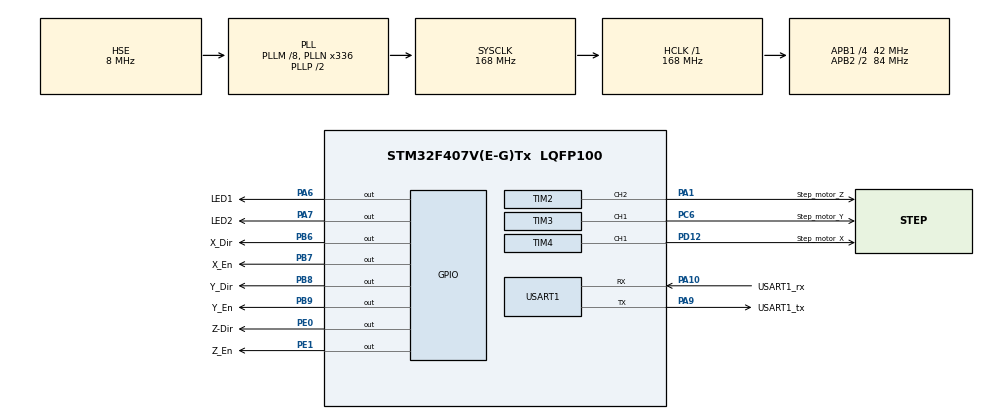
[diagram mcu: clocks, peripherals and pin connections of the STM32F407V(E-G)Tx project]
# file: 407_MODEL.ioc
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Dma.Request0=USART1_RX
Dma.USART1_RX.0.Direction=DMA_PERIPH_TO_MEMORY
Dma.USART1_RX.0.FIFOMode=DMA_FIFOMODE_DISABLE
Dma.USART1_RX.0.Instance=DMA2_Stream2
Dma.USART1_RX.0.MemDataAlignment=DMA_MDATAALIGN_BYTE
Dma.USART1_RX.0.MemInc=DMA_MINC_ENABLE
Dma.USART1_RX.0.Mode=DMA_NORMAL
Dma.USART1_RX.0.PeriphDataAlignment=DMA_PDATAALIGN_BYTE
Dma.USART1_RX.0.PeriphInc=DMA_PINC_DISABLE
Dma.USART1_RX.0.Priority=DMA_PRIORITY_HIGH
Mcu.Family=STM32F4
Mcu.Name=STM32F407V(E-G)Tx
Mcu.Package=LQFP100
NVIC.DMA2_Stream2_IRQn=true\:0\:2\:true\:false\:true\:false
NVIC.PriorityGroup=NVIC_PRIORITYGROUP_2
NVIC.TIM1_TRG_COM_TIM11_IRQn=true\:1\:0\:true\:false\:true\:true
NVIC.TIM1_UP_TIM10_IRQn=true\:1\:0\:true\:false\:true\:true
NVIC.TIM2_IRQn=true\:1\:1\:true\:false\:true\:true
NVIC.TIM3_IRQn=true\:1\:2\:true\:false\:true\:true
NVIC.TIM4_IRQn=true\:1\:3\:true\:false\:true\:true
NVIC.USART1_IRQn=true\:0\:1\:true\:false\:true\:true
PA1.GPIO_Label=Step_motor_Z
PA1.GPIO_Speed=GPIO_SPEED_FREQ_HIGH
PA1.Signal=S_TIM2_CH2
PA10.GPIO_Label=USART1_rx
PA10.Mode=Asynchronous
PA10.Signal=USART1_RX
PA6.GPIO_Label=LED1
PA6.GPIO_Speed=GPIO_SPEED_FREQ_HIGH
PA6.PinState=GPIO_PIN_SET
PA6.Signal=GPIO_Output
PA7.GPIO_Label=LED2
PA7.GPIO_Speed=GPIO_SPEED_FREQ_HIGH
PA7.PinState=GPIO_PIN_SET
PA7.Signal=GPIO_Output
PA9.GPIO_Label=USART1_tx
PA9.Mode=Asynchronous
PA9.Signal=USART1_TX
PB6.GPIO_Label=X_Dir
PB6.GPIO_Speed=GPIO_SPEED_FREQ_HIGH
PB6.PinState=GPIO_PIN_SET
PB6.Signal=GPIO_Output
PB7.GPIO_Label=X_En
PB7.GPIO_Speed=GPIO_SPEED_FREQ_HIGH
PB7.PinState=GPIO_PIN_SET
PB7.Signal=GPIO_Output
PB8.GPIO_Label=Y_Dir
PB8.GPIO_Speed=GPIO_SPEED_FREQ_HIGH
PB8.PinState=GPIO_PIN_SET
PB8.Signal=GPIO_Output
PB9.GPIO_Label=Y_En
PB9.GPIO_Speed=GPIO_SPEED_FREQ_MEDIUM
PB9.PinState=GPIO_PIN_SET
PB9.Signal=GPIO_Output
PC6.GPIO_Label=Step_motor_Y
PC6.GPIO_Speed=GPIO_SPEED_FREQ_HIGH
PC6.Signal=S_TIM3_CH1
PD12.GPIO_Label=Step_motor_X
PD12.GPIO_Speed=GPIO_SPEED_FREQ_HIGH
PD12.Signal=S_TIM4_CH1
PE0.GPIO_Label=Z-Dir
PE0.GPIO_Speed=GPIO_SPEED_FREQ_HIGH
PE0.Signal=GPIO_Output
PE1.GPIO_Label=Z_En
PE1.GPIO_Speed=GPIO_SPEED_FREQ_HIGH
PE1.PinState=GPIO_PIN_SET
PE1.Signal=GPIO_Output
PH0-OSC_IN.Mode=HSE-External-Oscillator
PH0-OSC_IN.Signal=RCC_OSC_IN
PH1-OSC_OUT.Mode=HSE-External-Oscillator
PH1-OSC_OUT.Signal=RCC_OSC_OUT
ProjectManager.HeapSize=0x200
ProjectManager.StackSize=0x400
ProjectManager.TargetToolchain=MDK-ARM V5
RCC.48MHZClocksFreq_Value=84000000
RCC.AHBFreq_Value=168000000
RCC.APB1CLKDivider=RCC_HCLK_DIV4
RCC.APB1Freq_Value=42000000
RCC.APB1TimFreq_Value=84000000
RCC.APB2CLKDivider=RCC_HCLK_DIV2
RCC.APB2Freq_Value=84000000
RCC.APB2TimFreq_Value=168000000
RCC.CortexFreq_Value=168000000
RCC.HCLKFreq_Value=168000000
RCC.HSE_VALUE=8000000
RCC.HSI_VALUE=16000000
RCC.LSE_VALUE=32768
RCC.PLLM=8
RCC.PLLN=336
RCC.PLLSourceVirtual=RCC_PLLSOURCE_HSE
RCC.SYSCLKFreq_VALUE=168000000
RCC.SYSCLKSource=RCC_SYSCLKSOURCE_PLLCLK
RCC.VCOOutputFreq_Value=336000000
SH.S_TIM2_CH2.0=TIM2_CH2,PWM Generation2 CH2
SH.S_TIM3_CH1.0=TIM3_CH1,PWM Generation1 CH1
SH.S_TIM4_CH1.0=TIM4_CH1,Output Compare1 CH1
TIM1.Period=1000
TIM1.Prescaler=83
TIM1.RepetitionCounter=2
TIM2.Channel-PWM\ Generation2\ CH2=TIM_CHANNEL_2
TIM2.Period=5000
TIM2.Prescaler=83
TIM2.Pulse-PWM\ Generation2\ CH2=2500
TIM3.Channel-PWM\ Generation1\ CH1=TIM_CHANNEL_1
TIM3.Period=5000
TIM3.Prescaler=83
TIM3.Pulse-PWM\ Generation1\ CH1=2500
TIM4.Channel-Output\ Compare1\ CH1=TIM_CHANNEL_1
TIM4.Period=5000
TIM4.Prescaler=83
TIM4.Pulse-Output\ Compare1\ CH1=2500
USART1.VirtualMode=VM_ASYNC
VP_TIM1_VS_ClockSourceINT.Mode=Internal
VP_TIM2_VS_ClockSourceINT.Mode=Internal
VP_TIM3_VS_ClockSourceINT.Mode=Internal
VP_TIM4_VS_ClockSourceINT.Mode=Internal
board=407_MODEL

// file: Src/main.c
/**
  ******************************************************************************
  * @file           : main.c
  * @brief          : Main program body
  ******************************************************************************
  ** This notice applies to any and all portions of this file
  * that are not between comment pairs USER CODE BEGIN and
  * USER CODE END. Other portions of this file, whether
  * inserted by the user or by software development tools
  * are owned by their respective copyright owners.
  *
  * COPYRIGHT(c) 2018 STMicroelectronics
  *
  * Redistribution and use in source and binary forms, with or without modification,
  * are permitted provided that the following conditions are met:
  *   1. Redistributions of source code must retain the above copyright notice,
  *      this list of conditions and the following disclaimer.
  *   2. Redistributions in binary form must reproduce the above copyright notice,
  *      this list of conditions and the following disclaimer in the documentation
  *      and/or other materials provided with the distribution.
  *   3. Neither the name of STMicroelectronics nor the names of its contributors
  *      may be used to endorse or promote products derived from this software
  *      without specific prior written permission.
  *
  * THIS SOFTWARE IS PROVIDED BY THE COPYRIGHT HOLDERS AND CONTRIBUTORS "AS IS"
  * AND ANY EXPRESS OR IMPLIED WARRANTIES, INCLUDING, BUT NOT LIMITED TO, THE
  * IMPLIED WARRANTIES OF MERCHANTABILITY AND FITNESS FOR A PARTICULAR PURPOSE ARE
  * DISCLAIMED. IN NO EVENT SHALL THE COPYRIGHT HOLDER OR CONTRIBUTORS BE LIABLE
  * FOR ANY DIRECT, INDIRECT, INCIDENTAL, SPECIAL, EXEMPLARY, OR CONSEQUENTIAL
  * DAMAGES (INCLUDING, BUT NOT LIMITED TO, PROCUREMENT OF SUBSTITUTE GOODS OR
  * SERVICES; LOSS OF USE, DATA, OR PROFITS; OR BUSINESS INTERRUPTION) HOWEVER
  * CAUSED AND ON ANY THEORY OF LIABILITY, WHETHER IN CONTRACT, STRICT LIABILITY,
  * OR TORT (INCLUDING NEGLIGENCE OR OTHERWISE) ARISING IN ANY WAY OUT OF THE USE
  * OF THIS SOFTWARE, EVEN IF ADVISED OF THE POSSIBILITY OF SUCH DAMAGE.
  *
  ******************************************************************************
  */
#include "main.h"
#include "stm32f4xx_hal.h"

TIM_HandleTypeDef htim1;
TIM_HandleTypeDef htim2;
TIM_HandleTypeDef htim3;
TIM_HandleTypeDef htim4;

UART_HandleTypeDef huart1;
DMA_HandleTypeDef hdma_usart1_rx;

/* USER CODE BEGIN PV */
/* Private variables ---------------------------------------------------------*/

/* USER CODE END PV */

void SystemClock_Config(void);
static void MX_GPIO_Init(void);
static void MX_DMA_Init(void);
static void MX_TIM1_Init(void);
static void MX_TIM2_Init(void);
static void MX_TIM3_Init(void);
static void MX_TIM4_Init(void);
static void MX_USART1_UART_Init(void);

void HAL_TIM_MspPostInit(TIM_HandleTypeDef *htim);

/* USER CODE BEGIN PFP */
/* Private function prototypes -----------------------------------------------*/

/* USER CODE END PFP */

int main(void)
{

  /* MCU Configuration----------------------------------------------------------*/

  /* Reset of all peripherals, Initializes the Flash interface and the Systick. */
  HAL_Init();

  /* Configure the system clock */
  SystemClock_Config();

  /* Initialize all configured peripherals */
  MX_GPIO_Init();
  MX_DMA_Init();
  MX_TIM1_Init();
  MX_TIM2_Init();
  MX_TIM3_Init();
  MX_TIM4_Init();
  MX_USART1_UART_Init();
  /* USER CODE BEGIN 2 */
  HAL_TIM_PWM_Start(&htim2, TIM_CHANNEL_2);
  /* USER CODE END 2 */

  /* Infinite loop */
  /* USER CODE BEGIN WHILE */
  while (1)
  {
		HAL_GPIO_WritePin(GPIOA, LED1_Pin|LED2_Pin, GPIO_PIN_RESET);
		HAL_Delay(1000);
		HAL_GPIO_WritePin(GPIOA, LED1_Pin|LED2_Pin, GPIO_PIN_SET);
		HAL_Delay(1000);
  /* USER CODE END WHILE */

  }

}

void SystemClock_Config(void)
{

  RCC_OscInitTypeDef RCC_OscInitStruct;
  RCC_ClkInitTypeDef RCC_ClkInitStruct;

    /**Configure the main internal regulator output voltage
    */
  __HAL_RCC_PWR_CLK_ENABLE();

  __HAL_PWR_VOLTAGESCALING_CONFIG(PWR_REGULATOR_VOLTAGE_SCALE1);

    /**Initializes the CPU, AHB and APB busses clocks
    */
  RCC_OscInitStruct.OscillatorType = RCC_OSCILLATORTYPE_HSE;
  RCC_OscInitStruct.HSEState = RCC_HSE_ON;
  RCC_OscInitStruct.PLL.PLLState = RCC_PLL_ON;
  RCC_OscInitStruct.PLL.PLLSource = RCC_PLLSOURCE_HSE;
  RCC_OscInitStruct.PLL.PLLM = 8;
  RCC_OscInitStruct.PLL.PLLN = 336;
  RCC_OscInitStruct.PLL.PLLP = RCC_PLLP_DIV2;
  RCC_OscInitStruct.PLL.PLLQ = 4;
  if (HAL_RCC_OscConfig(&RCC_OscInitStruct) != HAL_OK)
  {
    _Error_Handler(__FILE__, __LINE__);
  }

    /**Initializes the CPU, AHB and APB busses clocks
    */
  RCC_ClkInitStruct.ClockType = RCC_CLOCKTYPE_HCLK|RCC_CLOCKTYPE_SYSCLK
                              |RCC_CLOCKTYPE_PCLK1|RCC_CLOCKTYPE_PCLK2;
  RCC_ClkInitStruct.SYSCLKSource = RCC_SYSCLKSOURCE_PLLCLK;
  RCC_ClkInitStruct.AHBCLKDivider = RCC_SYSCLK_DIV1;
  RCC_ClkInitStruct.APB1CLKDivider = RCC_HCLK_DIV4;
  RCC_ClkInitStruct.APB2CLKDivider = RCC_HCLK_DIV2;

  if (HAL_RCC_ClockConfig(&RCC_ClkInitStruct, FLASH_LATENCY_5) != HAL_OK)
  {
    _Error_Handler(__FILE__, __LINE__);
  }

    /**Configure the Systick interrupt time
    */
  HAL_SYSTICK_Config(HAL_RCC_GetHCLKFreq()/1000);

    /**Configure the Systick
    */
  HAL_SYSTICK_CLKSourceConfig(SYSTICK_CLKSOURCE_HCLK);

  /* SysTick_IRQn interrupt configuration */
  HAL_NVIC_SetPriority(SysTick_IRQn, 0, 0);
}

/* TIM1 init function */
static void MX_TIM1_Init(void)
{

  TIM_ClockConfigTypeDef sClockSourceConfig;
  TIM_MasterConfigTypeDef sMasterConfig;

  htim1.Instance = TIM1;
  htim1.Init.Prescaler = 83;
  htim1.Init.CounterMode = TIM_COUNTERMODE_UP;
  htim1.Init.Period = 1000;
  htim1.Init.ClockDivision = TIM_CLOCKDIVISION_DIV1;
  htim1.Init.RepetitionCounter = 2;
  if (HAL_TIM_Base_Init(&htim1) != HAL_OK)
  {
    _Error_Handler(__FILE__, __LINE__);
  }

  sClockSourceConfig.ClockSource = TIM_CLOCKSOURCE_INTERNAL;
  if (HAL_TIM_ConfigClockSource(&htim1, &sClockSourceConfig) != HAL_OK)
  {
    _Error_Handler(__FILE__, __LINE__);
  }

  sMasterConfig.MasterOutputTrigger = TIM_TRGO_RESET;
  sMasterConfig.MasterSlaveMode = TIM_MASTERSLAVEMODE_DISABLE;
  if (HAL_TIMEx_MasterConfigSynchronization(&htim1, &sMasterConfig) != HAL_OK)
  {
    _Error_Handler(__FILE__, __LINE__);
  }

}

/* TIM2 init function */
static void MX_TIM2_Init(void)
{

  TIM_ClockConfigTypeDef sClockSourceConfig;
  TIM_MasterConfigTypeDef sMasterConfig;
  TIM_OC_InitTypeDef sConfigOC;

  htim2.Instance = TIM2;
  htim2.Init.Prescaler = 83;
  htim2.Init.CounterMode = TIM_COUNTERMODE_UP;
  htim2.Init.Period = 500;
  htim2.Init.ClockDivision = TIM_CLOCKDIVISION_DIV1;
  if (HAL_TIM_Base_Init(&htim2) != HAL_OK)
  {
    _Error_Handler(__FILE__, __LINE__);
  }

  sClockSourceConfig.ClockSource = TIM_CLOCKSOURCE_INTERNAL;
  if (HAL_TIM_ConfigClockSource(&htim2, &sClockSourceConfig) != HAL_OK)
  {
    _Error_Handler(__FILE__, __LINE__);
  }

  if (HAL_TIM_PWM_Init(&htim2) != HAL_OK)
  {
    _Error_Handler(__FILE__, __LINE__);
  }

  sMasterConfig.MasterOutputTrigger = TIM_TRGO_RESET;
  sMasterConfig.MasterSlaveMode = TIM_MASTERSLAVEMODE_DISABLE;
  if (HAL_TIMEx_MasterConfigSynchronization(&htim2, &sMasterConfig) != HAL_OK)
  {
    _Error_Handler(__FILE__, __LINE__);
  }

  sConfigOC.OCMode = TIM_OCMODE_PWM1;
  sConfigOC.Pulse = 250;
  sConfigOC.OCPolarity = TIM_OCPOLARITY_HIGH;
  sConfigOC.OCFastMode = TIM_OCFAST_DISABLE;
  if (HAL_TIM_PWM_ConfigChannel(&htim2, &sConfigOC, TIM_CHANNEL_2) != HAL_OK)
  {
    _Error_Handler(__FILE__, __LINE__);
  }

  HAL_TIM_MspPostInit(&htim2);

}

/* TIM3 init function */
static void MX_TIM3_Init(void)
{

  TIM_ClockConfigTypeDef sClockSourceConfig;
  TIM_MasterConfigTypeDef sMasterConfig;
  TIM_OC_InitTypeDef sConfigOC;

  htim3.Instance = TIM3;
  htim3.Init.Prescaler = 83;
  htim3.Init.CounterMode = TIM_COUNTERMODE_UP;
  htim3.Init.Period = 5000;
  htim3.Init.ClockDivision = TIM_CLOCKDIVISION_DIV1;
  if (HAL_TIM_Base_Init(&htim3) != HAL_OK)
  {
    _Error_Handler(__FILE__, __LINE__);
  }

  sClockSourceConfig.ClockSource = TIM_CLOCKSOURCE_INTERNAL;
  if (HAL_TIM_ConfigClockSource(&htim3, &sClockSourceConfig) != HAL_OK)
  {
    _Error_Handler(__FILE__, __LINE__);
  }

  if (HAL_TIM_PWM_Init(&htim3) != HAL_OK)
  {
    _Error_Handler(__FILE__, __LINE__);
  }

  sMasterConfig.MasterOutputTrigger = TIM_TRGO_RESET;
  sMasterConfig.MasterSlaveMode = TIM_MASTERSLAVEMODE_DISABLE;
  if (HAL_TIMEx_MasterConfigSynchronization(&htim3, &sMasterConfig) != HAL_OK)
  {
    _Error_Handler(__FILE__, __LINE__);
  }

  sConfigOC.OCMode = TIM_OCMODE_PWM1;
  sConfigOC.Pulse = 2500;
  sConfigOC.OCPolarity = TIM_OCPOLARITY_HIGH;
  sConfigOC.OCFastMode = TIM_OCFAST_DISABLE;
  if (HAL_TIM_PWM_ConfigChannel(&htim3, &sConfigOC, TIM_CHANNEL_1) != HAL_OK)
  {
    _Error_Handler(__FILE__, __LINE__);
  }

  HAL_TIM_MspPostInit(&htim3);

}

/* TIM4 init function */
static void MX_TIM4_Init(void)
{

  TIM_ClockConfigTypeDef sClockSourceConfig;
  TIM_MasterConfigTypeDef sMasterConfig;
  TIM_OC_InitTypeDef sConfigOC;

  htim4.Instance = TIM4;
  htim4.Init.Prescaler = 83;
  htim4.Init.CounterMode = TIM_COUNTERMODE_UP;
  htim4.Init.Period = 5000;
  htim4.Init.ClockDivision = TIM_CLOCKDIVISION_DIV1;
  if (HAL_TIM_Base_Init(&htim4) != HAL_OK)
  {
    _Error_Handler(__FILE__, __LINE__);
  }

  sClockSourceConfig.ClockSource = TIM_CLOCKSOURCE_INTERNAL;
  if (HAL_TIM_ConfigClockSource(&htim4, &sClockSourceConfig) != HAL_OK)
  {
    _Error_Handler(__FILE__, __LINE__);
  }

  if (HAL_TIM_OC_Init(&htim4) != HAL_OK)
  {
    _Error_Handler(__FILE__, __LINE__);
  }

  sMasterConfig.MasterOutputTrigger = TIM_TRGO_RESET;
  sMasterConfig.MasterSlaveMode = TIM_MASTERSLAVEMODE_DISABLE;
  if (HAL_TIMEx_MasterConfigSynchronization(&htim4, &sMasterConfig) != HAL_OK)
  {
    _Error_Handler(__FILE__, __LINE__);
  }

  sConfigOC.OCMode = TIM_OCMODE_TIMING;
  sConfigOC.Pulse = 2500;
  sConfigOC.OCPolarity = TIM_OCPOLARITY_HIGH;
  sConfigOC.OCFastMode = TIM_OCFAST_DISABLE;
  if (HAL_TIM_OC_ConfigChannel(&htim4, &sConfigOC, TIM_CHANNEL_1) != HAL_OK)
  {
    _Error_Handler(__FILE__, __LINE__);
  }

  HAL_TIM_MspPostInit(&htim4);

}

/* USART1 init function */
static void MX_USART1_UART_Init(void)
{

  huart1.Instance = USART1;
  huart1.Init.BaudRate = 115200;
  huart1.Init.WordLength = UART_WORDLENGTH_8B;
  huart1.Init.StopBits = UART_STOPBITS_1;
  huart1.Init.Parity = UART_PARITY_NONE;
  huart1.Init.Mode = UART_MODE_TX_RX;
  huart1.Init.HwFlowCtl = UART_HWCONTROL_NONE;
  huart1.Init.OverSampling = UART_OVERSAMPLING_16;
  if (HAL_UART_Init(&huart1) != HAL_OK)
  {
    _Error_Handler(__FILE__, __LINE__);
  }

}

static void MX_DMA_Init(void)
{
  /* DMA controller clock enable */
  __HAL_RCC_DMA2_CLK_ENABLE();

  /* DMA interrupt init */
  /* DMA2_Stream2_IRQn interrupt configuration */
  HAL_NVIC_SetPriority(DMA2_Stream2_IRQn, 0, 2);
  HAL_NVIC_EnableIRQ(DMA2_Stream2_IRQn);

}

/** Configure pins as
        * Analog
        * Input
        * Output
        * EVENT_OUT
        * EXTI
*/
static void MX_GPIO_Init(void)
{

  GPIO_InitTypeDef GPIO_InitStruct;

  /* GPIO Ports Clock Enable */
  __HAL_RCC_GPIOH_CLK_ENABLE();
  __HAL_RCC_GPIOA_CLK_ENABLE();
  __HAL_RCC_GPIOD_CLK_ENABLE();
  __HAL_RCC_GPIOC_CLK_ENABLE();
  __HAL_RCC_GPIOB_CLK_ENABLE();
  __HAL_RCC_GPIOE_CLK_ENABLE();

  /*Configure GPIO pin Output Level */
  HAL_GPIO_WritePin(GPIOA, LED1_Pin|LED2_Pin, GPIO_PIN_SET);

  /*Configure GPIO pin Output Level */
  HAL_GPIO_WritePin(GPIOB, X_Dir_Pin|X_En_Pin|Y_Dir_Pin|Y_En_Pin, GPIO_PIN_SET);

  /*Configure GPIO pin Output Level */
  HAL_GPIO_WritePin(Z_Dir_GPIO_Port, Z_Dir_Pin, GPIO_PIN_RESET);

  /*Configure GPIO pin Output Level */
  HAL_GPIO_WritePin(Z_En_GPIO_Port, Z_En_Pin, GPIO_PIN_SET);

  /*Configure GPIO pins : LED1_Pin LED2_Pin */
  GPIO_InitStruct.Pin = LED1_Pin|LED2_Pin;
  GPIO_InitStruct.Mode = GPIO_MODE_OUTPUT_PP;
  GPIO_InitStruct.Pull = GPIO_NOPULL;
  GPIO_InitStruct.Speed = GPIO_SPEED_FREQ_HIGH;
  HAL_GPIO_Init(GPIOA, &GPIO_InitStruct);

  /*Configure GPIO pins : X_Dir_Pin X_En_Pin Y_Dir_Pin */
  GPIO_InitStruct.Pin = X_Dir_Pin|X_En_Pin|Y_Dir_Pin;
  GPIO_InitStruct.Mode = GPIO_MODE_OUTPUT_PP;
  GPIO_InitStruct.Pull = GPIO_NOPULL;
  GPIO_InitStruct.Speed = GPIO_SPEED_FREQ_HIGH;
  HAL_GPIO_Init(GPIOB, &GPIO_InitStruct);

  /*Configure GPIO pin : Y_En_Pin */
  GPIO_InitStruct.Pin = Y_En_Pin;
  GPIO_InitStruct.Mode = GPIO_MODE_OUTPUT_PP;
  GPIO_InitStruct.Pull = GPIO_NOPULL;
  GPIO_InitStruct.Speed = GPIO_SPEED_FREQ_MEDIUM;
  HAL_GPIO_Init(Y_En_GPIO_Port, &GPIO_InitStruct);

  /*Configure GPIO pins : Z_Dir_Pin Z_En_Pin */
  GPIO_InitStruct.Pin = Z_Dir_Pin|Z_En_Pin;
  GPIO_InitStruct.Mode = GPIO_MODE_OUTPUT_PP;
  GPIO_InitStruct.Pull = GPIO_NOPULL;
  GPIO_InitStruct.Speed = GPIO_SPEED_FREQ_HIGH;
  HAL_GPIO_Init(GPIOE, &GPIO_InitStruct);

}

void _Error_Handler(char *file, int line)
{
  while(1)
  {
  }
}

/************************ (C) COPYRIGHT STMicroelectronics *****END OF FILE****/
